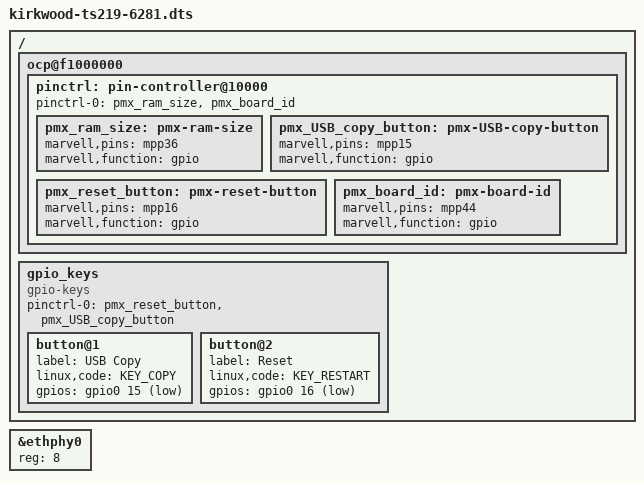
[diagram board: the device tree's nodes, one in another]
/dts-v1/;

#include "kirkwood.dtsi"
#include "kirkwood-6281.dtsi"
#include "kirkwood-ts219.dtsi"

/ {
	ocp@f1000000 {
		pinctrl: pin-controller@10000 {

			pinctrl-0 = <&pmx_ram_size &pmx_board_id>;
			pinctrl-names = "default";

			pmx_ram_size: pmx-ram-size {
				/* RAM: 0: 256 MB, 1: 512 MB */
				marvell,pins = "mpp36";
				marvell,function = "gpio";
			};
			pmx_USB_copy_button: pmx-USB-copy-button {
				marvell,pins = "mpp15";
				marvell,function = "gpio";
			};
			pmx_reset_button: pmx-reset-button {
				marvell,pins = "mpp16";
				marvell,function = "gpio";
			};
			pmx_board_id: pmx-board-id {
				/* 0: TS-11x, 1: TS-21x */
				marvell,pins = "mpp44";
				marvell,function = "gpio";
			};
		};
	};

	gpio_keys {
		compatible = "gpio-keys";
		#address-cells = <1>;
		#size-cells = <0>;
		pinctrl-0 = <&pmx_reset_button &pmx_USB_copy_button>;
		pinctrl-names = "default";

		button@1 {
			label = "USB Copy";
			linux,code = <KEY_COPY>;
			gpios = <&gpio0 15 GPIO_ACTIVE_LOW>;
		};
		button@2 {
			label = "Reset";
			linux,code = <KEY_RESTART>;
			gpios = <&gpio0 16 GPIO_ACTIVE_LOW>;
		};
	};
};

&ethphy0 { reg = <8>; };
